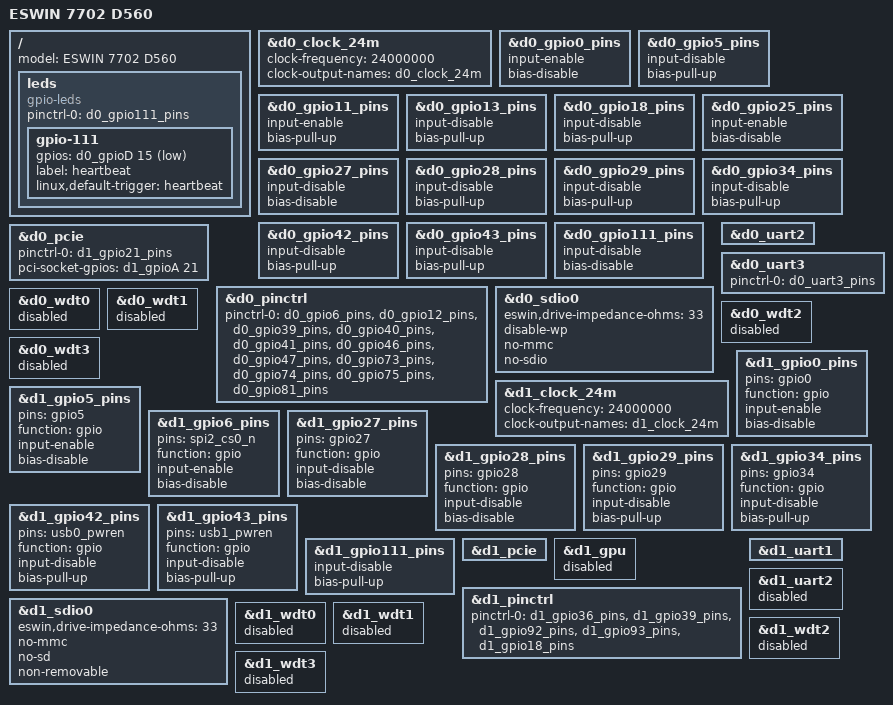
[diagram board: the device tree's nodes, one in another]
// SPDX-License-Identifier: GPL-2.0
/*
 * Device Tree file for Eswin EIC7702 SoC.
 *
 * Copyright 2026, Beijing ESWIN Computing Technology Co., Ltd.. All rights reserved.
 * SPDX-License-Identifier: GPL-2.0
 *
 * This program is free software: you can redistribute it and/or modify
 * it under the terms of the GNU General Public License as published by
 * the Free Software Foundation, version 2.
 *
 * This program is distributed in the hope that it will be useful,
 * but WITHOUT ANY WARRANTY; without even the implied warranty of
 * MERCHANTABILITY or FITNESS FOR A PARTICULAR PURPOSE.  See the
 * GNU General Public License for more details.
 *
 * You should have received a copy of the GNU General Public License
 * along with this program.  If not, see <https://www.gnu.org/licenses/>.
 */

/dts-v1/;

#include "eic7702-som560.dtsi"

/ {
	model = "ESWIN 7702 D560";

	/* die0 gpio111 system led */
	leds {
		compatible = "gpio-leds";
		pinctrl-names = "default";
		pinctrl-0 = <&d0_gpio111_pins>;

		gpio-111 {
			gpios = <&d0_gpioD 15 GPIO_ACTIVE_LOW>;
			label = "heartbeat";
			linux,default-trigger = "heartbeat";
		};
	};
};

&d0_clock_24m {
	clock-frequency = <24000000>;
	clock-output-names = "d0_clock_24m";
};

&d0_gpio0_pins {
	input-enable;
	bias-disable;
};

&d0_gpio5_pins {
	input-disable;
	bias-pull-up;
};

&d0_gpio11_pins {
	input-enable;
	bias-pull-up;
};

&d0_gpio13_pins {
	input-disable;
	bias-pull-up;
};

&d0_gpio18_pins {
	input-disable;
	bias-pull-up;
};

&d0_gpio25_pins {
	input-enable;
	bias-disable;
};

&d0_gpio27_pins {
	input-disable;
	bias-disable;
};

&d0_gpio28_pins {
	input-disable;
	bias-pull-up;
};

&d0_gpio29_pins {
	input-disable;
	bias-pull-up;
};

&d0_gpio34_pins {
	input-disable;
	bias-pull-up;
};

&d0_gpio42_pins {
	input-disable;
	bias-pull-up;
};

&d0_gpio43_pins {
	input-disable;
	bias-pull-up;
};

&d0_gpio111_pins {
	input-disable;
	bias-disable;
};

&d0_pcie {
	status = "okay";
	pinctrl-names = "default";
	pinctrl-0 = <&d1_gpio21_pins>;
	pci-socket-gpios = <&d1_gpioA 21 GPIO_ACTIVE_HIGH>;
};

&d0_pinctrl {
	/* pin header */
	status = "okay";
	pinctrl-names = "default";
	pinctrl-0 = <&d0_gpio6_pins &d0_gpio12_pins &d0_gpio39_pins
				&d0_gpio40_pins &d0_gpio41_pins &d0_gpio46_pins
				&d0_gpio47_pins &d0_gpio73_pins &d0_gpio74_pins
				&d0_gpio75_pins &d0_gpio81_pins>;
};

&d0_sdio0 {
	eswin,drive-impedance-ohms = <33>;
	disable-wp;
	no-mmc;
	no-sdio;
	status = "okay";
};

&d0_uart2 {
	/* connect mcu */
	status = "okay";
};

&d0_uart3 {
	/* pin header */
	status = "okay";
	pinctrl-names = "default";
	pinctrl-0 = <&d0_uart3_pins>;
};

&d0_wdt0 {
	status = "disabled";
};

&d0_wdt1 {
	status = "disabled";
};

&d0_wdt2 {
	status = "disabled";
};

&d0_wdt3 {
	status = "disabled";
};

&d1_clock_24m {
	clock-frequency = <24000000>;
	clock-output-names = "d1_clock_24m";
};

&d1_gpio0_pins {
	pins = "gpio0";
	function = "gpio";
	input-enable;
	bias-disable;
};

&d1_gpio5_pins {
	pins = "gpio5";
	function = "gpio";
	input-enable;
	bias-disable;
};

&d1_gpio6_pins {
	pins = "spi2_cs0_n";
	function = "gpio";
	input-enable;
	bias-disable;
};

&d1_gpio27_pins {
	pins = "gpio27";
	function = "gpio";
	input-disable;
	bias-disable;
};

&d1_gpio28_pins {
	pins = "gpio28";
	function = "gpio";
	input-disable;
	bias-disable;
};

&d1_gpio29_pins {
	pins = "gpio29";
	function = "gpio";
	input-disable;
	bias-pull-up;
};

&d1_gpio34_pins {
	pins = "gpio34";
	function = "gpio";
	input-disable;
	bias-pull-up;
};

&d1_gpio42_pins {
	pins = "usb0_pwren";
	function = "gpio";
	input-disable;
	bias-pull-up;
};

&d1_gpio43_pins {
	pins = "usb1_pwren";
	function = "gpio";
	input-disable;
	bias-pull-up;
};

&d1_gpio111_pins {
	input-disable;
	bias-pull-up;
};

&d1_pcie {
	status = "okay";
};

&d1_gpu {
	status = "disabled";
};

&d1_pinctrl {
	/* pin header */
	status = "okay";
	pinctrl-names = "default";
	pinctrl-0 = <&d1_gpio36_pins &d1_gpio39_pins
				&d1_gpio92_pins &d1_gpio93_pins
				&d1_gpio18_pins>;
};

&d1_sdio0 {
	eswin,drive-impedance-ohms = <33>;
	no-mmc;
	no-sd;
	non-removable;
	status = "okay";
};

&d1_uart1 {
	/* BT M.2 KEY-E */
	status = "okay";
};

&d1_uart2 {
	/* unused */
	status = "disabled";
};

&d1_wdt0 {
	status = "disabled";
};

&d1_wdt1 {
	status = "disabled";
};

&d1_wdt2 {
	status = "disabled";
};

&d1_wdt3 {
	status = "disabled";
};

/******** pin headers *********
     pin : function
       3 : D0 I2C5 SDA
       5 : D0 I2C5 SCL
       7 : D0 GPIO46
       8 : D0 UART3 TX
      10 : D0 UART3 RX
      11 : D0 GPIO6
      12 : D0 GPIO12
      13 : D0 GPIO5 (x)
      15 : D0 GPIO81
      16 : D0 GPIO47
      18 : D0 SPI1 D3(GPIO40)
      19 : D0 SPI1 D0
      21 : D0 SPI1 D1
      22 : D0 SPI1 D2(GPIO39)
      23 : D0 SPI1 CLK
      24 : D0 SPI1 CS0
      26 : D0 SPI1 CS1(GPIO41)
      27 : D1 I2C9 SDA
      28 : D1 I2C9 SCL
      29 : D1 GPIO93
      31 : D1 GPIO92
      32 : D1 GPIO35 (x)
      33 : D1 GPIO36
      35 : D1 GPIO39
      36 : D0 GPIO79 (x)
      37 : D0 GPIO74
      38 : D0 GPIO75
      40 : D0 GPIO73
*********************************/

/* die0 GPIO Function Description

	gpio0   : pcie prstn(I)
	gpio11  : tmp alert(I)
	gpio13  : tf card detect(I)
	gpio18  : ina226 alert(I)
	gpio25  : front panel audio insert detection(I)
	gpio27  : sata act(O)
	gpio28  : to mcu pb5
	gpio29  : gphy0 resetn(O)
	gpio34  : gphy1 resetn(O)
	gpio42  : usb0 pwren(O)
	gpio43  : usb1 pwren(O)
	gpio111 : sys run led(O)
*/
/* die1 GPIO Function Description

	gpio0   : pcie prstn(I)
	gpio5   : classis fan1 fantach
	gpio6   : classis fan2 fantach
	gpio27  : to mcu pb3
	gpio28  : to mcu pb4
	gpio29  : gphy0 resetn(O)
	gpio34  : gphy1 resetn(O)
	gpio42  : usb0 pwren(O)
	gpio43  : usb1 pwren(O)
*/
